AUTOSAR XML (schema 00047)
package /AppMode/ApplicationSwComponentTypes
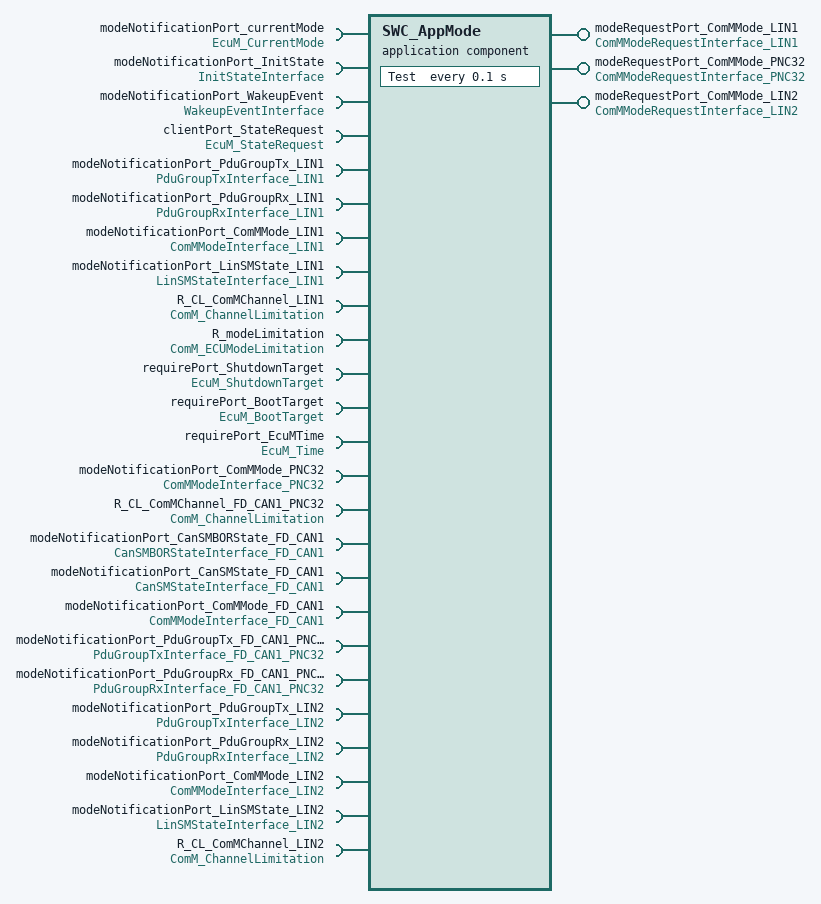
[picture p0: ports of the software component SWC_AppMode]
  application sw component type SWC_AppMode
    4 x require port:
      modeNotificationPort_currentMode: mode-switch-receiver-com-spec{enhanced-mode-api=true, mode-group=currentMode, supports-asynchronous-mode-switch=true}, required-interface=EcuM_CurrentMode
      modeNotificationPort_InitState: mode-switch-receiver-com-spec{enhanced-mode-api=true, mode-group=InitState, supports-asynchronous-mode-switch=true}, required-interface=InitStateInterface
      modeNotificationPort_WakeupEvent: mode-switch-receiver-com-spec{enhanced-mode-api=true, mode-group=WakeupEvent, supports-asynchronous-mode-switch=true}, required-interface=WakeupEventInterface
      clientPort_StateRequest: required-com-specs=[ReleaseRUN, RequestRUN, RequestSleep, RequestReset, RequestOff, ReleasePOST_RUN, RequestPOST_RUN], required-interface=EcuM_StateRequest
    provide port modeRequestPort_ComMMode_LIN1: nonqueued-sender-com-spec=data-element=ComMMode_LIN1, provided-interface=ComMModeRequestInterface_LIN1
    10 x require port:
      modeNotificationPort_PduGroupTx_LIN1: mode-switch-receiver-com-spec{enhanced-mode-api=true, mode-group=PduGroupTx_LIN1, supports-asynchronous-mode-switch=true}, required-interface=PduGroupTxInterface_LIN1
      modeNotificationPort_PduGroupRx_LIN1: mode-switch-receiver-com-spec{enhanced-mode-api=true, mode-group=PduGroupRx_LIN1, supports-asynchronous-mode-switch=true}, required-interface=PduGroupRxInterface_LIN1
      modeNotificationPort_ComMMode_LIN1: mode-switch-receiver-com-spec{enhanced-mode-api=true, mode-group=ComMMode_LIN1, supports-asynchronous-mode-switch=true}, required-interface=ComMModeInterface_LIN1
      modeNotificationPort_LinSMState_LIN1: mode-switch-receiver-com-spec{enhanced-mode-api=true, mode-group=LinSMState_LIN1, supports-asynchronous-mode-switch=true}, required-interface=LinSMStateInterface_LIN1
      R_CL_ComMChannel_LIN1: required-com-specs=[LimitChannelToNoComMode, GetInhibitionStatus], required-interface=ComM_ChannelLimitation
      R_modeLimitation: required-com-specs=[SetECUGroupClassification, LimitECUToNoComMode], required-interface=ComM_ECUModeLimitation
      requirePort_ShutdownTarget: required-com-specs=[GetLastShutdownTarget, GetShutdownTarget, SelectShutdownTarget], required-interface=EcuM_ShutdownTarget
      requirePort_BootTarget: required-com-specs=[GetBootTarget, SelectBootTarget], required-interface=EcuM_BootTarget
      requirePort_EcuMTime: required-com-specs=[GetWakeupTime, GetCurrentTime], required-interface=EcuM_Time
      modeNotificationPort_ComMMode_PNC32: mode-switch-receiver-com-spec{enhanced-mode-api=true, mode-group=ComMMode_PNC32, supports-asynchronous-mode-switch=true}, required-interface=ComMModeInterface_PNC32
    provide port modeRequestPort_ComMMode_PNC32: nonqueued-sender-com-spec=ComMMode_PNC32, provided-interface=ComMModeRequestInterface_PNC32
    6 x require port:
      R_CL_ComMChannel_FD_CAN1_PNC32: required-com-specs=[LimitChannelToNoComMode, GetInhibitionStatus], required-interface=ComM_ChannelLimitation
      modeNotificationPort_CanSMBORState_FD_CAN1: mode-switch-receiver-com-spec{enhanced-mode-api=true, mode-group=CanSMBORState_FD_CAN1, supports-asynchronous-mode-switch=true}, required-interface=CanSMBORStateInterface_FD_CAN1
      modeNotificationPort_CanSMState_FD_CAN1: mode-switch-receiver-com-spec{enhanced-mode-api=true, mode-group=CanSMState_FD_CAN1, supports-asynchronous-mode-switch=true}, required-interface=CanSMStateInterface_FD_CAN1
      modeNotificationPort_ComMMode_FD_CAN1: mode-switch-receiver-com-spec{enhanced-mode-api=true, mode-group=ComMMode_FD_CAN1, supports-asynchronous-mode-switch=true}, required-interface=ComMModeInterface_FD_CAN1
      modeNotificationPort_PduGroupTx_FD_CAN1_PNC32: mode-switch-receiver-com-spec{enhanced-mode-api=true, mode-group=PduGroupTx_FD_CAN1_PNC32, supports-asynchronous-mode-switch=true}, required-interface=PduGroupTxInterface_FD_CAN1_PNC32
      modeNotificationPort_PduGroupRx_FD_CAN1_PNC32: mode-switch-receiver-com-spec{enhanced-mode-api=true, mode-group=PduGroupRx_FD_CAN1_PNC32, supports-asynchronous-mode-switch=true}, required-interface=PduGroupRxInterface_FD_CAN1_PNC32
    provide port modeRequestPort_ComMMode_LIN2: nonqueued-sender-com-spec=ComMMode_LIN2, provided-interface=ComMModeRequestInterface_LIN2
    5 x require port:
      modeNotificationPort_PduGroupTx_LIN2: mode-switch-receiver-com-spec{enhanced-mode-api=true, mode-group=PduGroupTx_LIN2, supports-asynchronous-mode-switch=true}, required-interface=PduGroupTxInterface_LIN2
      modeNotificationPort_PduGroupRx_LIN2: mode-switch-receiver-com-spec{enhanced-mode-api=true, mode-group=PduGroupRx_LIN2, supports-asynchronous-mode-switch=true}, required-interface=PduGroupRxInterface_LIN2
      modeNotificationPort_ComMMode_LIN2: mode-switch-receiver-com-spec{enhanced-mode-api=true, mode-group=ComMMode_LIN2, supports-asynchronous-mode-switch=true}, required-interface=ComMModeInterface_LIN2
      modeNotificationPort_LinSMState_LIN2: mode-switch-receiver-com-spec{enhanced-mode-api=true, mode-group=LinSMState_LIN2, supports-asynchronous-mode-switch=true}, required-interface=LinSMStateInterface_LIN2
      R_CL_ComMChannel_LIN2: required-com-specs=[LimitChannelToNoComMode, GetInhibitionStatus], required-interface=ComM_ChannelLimitation
    behavior SwcIB_AppMode: data-type-mapping=[MAP_AppMode, MAP_ComMMode, MAP_PduRouter, EcuModeMap, MAP_CanSMBORState, MAP_InitState, MAP_PduGroup, MAP_WakeupEvent, MAP_LinSMState, MAP_ComMMode_PNC], handle-termination-and-restart=NO-SUPPORT
      timing event TE_AppMode_Test: start-on-event=Test, period=0.1
        disabled-mode:
          modeNotificationPort_currentMode.currentMode.ECUM_STATE_STARTUP_ONE
          modeNotificationPort_currentMode.currentMode.ECUM_STATE_STARTUP_TWO
          modeNotificationPort_currentMode.currentMode.ECUM_STATE_STARTUP_THREE
      31 x swc mode switch event, all with activation=ON-ENTRY:
        SMSE_Entry_EcuModeSwitched_modeNotificationPort_CurrentMode_CurrentMode_ECUM_STATE_APP_POST_RUN: start-on-event=EcuModeSwitched, mode=modeNotificationPort_currentMode.currentMode.ECUM_STATE_APP_POST_RUN
        SMSE_Entry_EcuModeSwitched_modeNotificationPort_CurrentMode_CurrentMode_ECUM_STATE_APP_RUN: start-on-event=EcuModeSwitched, mode=modeNotificationPort_currentMode.currentMode.ECUM_STATE_APP_RUN
        SMSE_Entry_EcuModeSwitched_modeNotificationPort_CurrentMode_CurrentMode_ECUM_STATE_OFF: start-on-event=EcuModeSwitched, mode=modeNotificationPort_currentMode.currentMode.ECUM_STATE_OFF
        SMSE_Entry_EcuModeSwitched_modeNotificationPort_CurrentMode_CurrentMode_ECUM_STATE_PREP_SHUTDOWN: start-on-event=EcuModeSwitched, mode=modeNotificationPort_currentMode.currentMode.ECUM_STATE_PREP_SHUTDOWN
        SMSE_Entry_EcuModeSwitched_modeNotificationPort_CurrentMode_CurrentMode_ECUM_STATE_RESET: start-on-event=EcuModeSwitched, mode=modeNotificationPort_currentMode.currentMode.ECUM_STATE_RESET
        SMSE_Entry_EcuModeSwitched_modeNotificationPort_CurrentMode_CurrentMode_ECUM_STATE_RUN: start-on-event=EcuModeSwitched, mode=modeNotificationPort_currentMode.currentMode.ECUM_STATE_RUN
        SMSE_Entry_EcuModeSwitched_modeNotificationPort_CurrentMode_CurrentMode_ECUM_STATE_SHUTDOWN: start-on-event=EcuModeSwitched, mode=modeNotificationPort_currentMode.currentMode.ECUM_STATE_SHUTDOWN
        SMSE_Entry_EcuModeSwitched_modeNotificationPort_CurrentMode_CurrentMode_ECUM_STATE_SLEEP: start-on-event=EcuModeSwitched, mode=modeNotificationPort_currentMode.currentMode.ECUM_STATE_SLEEP
        SMSE_Entry_InitCompleted_modeNotificationPort_InitState_InitState_COMPLETE: start-on-event=InitCompleted, mode=modeNotificationPort_InitState.InitState.COMPLETE
        SMSE_Entry_ComMModeSwitched_LIN1_modeNotificationPort_ComMMode_LIN1_ComMMode_LIN1_FULL_COM: start-on-event=ComMModeSwitched_LIN1, mode=modeNotificationPort_ComMMode_LIN1.ComMMode_LIN1.FULL_COM
        SMSE_Entry_ComMModeSwitched_LIN1_modeNotificationPort_ComMMode_LIN1_ComMMode_LIN1_NO_COM: start-on-event=ComMModeSwitched_LIN1, mode=modeNotificationPort_ComMMode_LIN1.ComMMode_LIN1.NO_COM
        SMSE_Entry_ComMModeSwitched_LIN1_modeNotificationPort_ComMMode_LIN1_ComMMode_LIN1_SILENT_COM: start-on-event=ComMModeSwitched_LIN1, mode=modeNotificationPort_ComMMode_LIN1.ComMMode_LIN1.SILENT_COM
        SMSE_Entry_PduGroupSwitched_FD_CAN1_PNC32_Tx_modeNotificationPort_PduGroupTx_FD_CAN1_PNC32_PduGroupTx_FD_CAN1_PNC32_START: start-on-event=PduGroupSwitched_FD_CAN1_PNC32_Tx, mode=modeNotificationPort_PduGroupTx_FD_CAN1_PNC32.PduGroupTx_FD_CAN1_PNC32.START
        SMSE_Entry_PduGroupSwitched_FD_CAN1_PNC32_Tx_modeNotificationPort_PduGroupTx_FD_CAN1_PNC32_PduGroupTx_FD_CAN1_PNC32_STOP: start-on-event=PduGroupSwitched_FD_CAN1_PNC32_Tx, mode=modeNotificationPort_PduGroupTx_FD_CAN1_PNC32.PduGroupTx_FD_CAN1_PNC32.STOP
        SMSE_Entry_CanSMBorStateSwitched_FD_CAN1_modeNotificationPort_CanSMBORState_FD_CAN1_CanSMBORState_FD_CAN1_COMPLETE: start-on-event=CanSMBorStateSwitched_FD_CAN1, mode=modeNotificationPort_CanSMBORState_FD_CAN1.CanSMBORState_FD_CAN1.COMPLETE
        SMSE_Entry_CanSMBorStateSwitched_FD_CAN1_modeNotificationPort_CanSMBORState_FD_CAN1_CanSMBORState_FD_CAN1_START: start-on-event=CanSMBorStateSwitched_FD_CAN1, mode=modeNotificationPort_CanSMBORState_FD_CAN1.CanSMBORState_FD_CAN1.START
        SMSE_Entry_ComMModeSwitched_FD_CAN1_PNC32_modeNotificationPort_ComMMode_PNC32_ComMMode_PNC32_PNC_FULL_COMMUNICATION: start-on-event=ComMModeSwitched_FD_CAN1_PNC32, mode=modeNotificationPort_ComMMode_PNC32.ComMMode_PNC32.PNC_FULL_COMMUNICATION
        SMSE_Entry_ComMModeSwitched_FD_CAN1_PNC32_modeNotificationPort_ComMMode_PNC32_ComMMode_PNC32_PNC_NO_COMMUNICATION: start-on-event=ComMModeSwitched_FD_CAN1_PNC32, mode=modeNotificationPort_ComMMode_PNC32.ComMMode_PNC32.PNC_NO_COMMUNICATION
        SMSE_Entry_ComMModeSwitched_FD_CAN1_PNC32_modeNotificationPort_ComMMode_PNC32_ComMMode_PNC32_PNC_PREPARE_SLEEP: start-on-event=ComMModeSwitched_FD_CAN1_PNC32, mode=modeNotificationPort_ComMMode_PNC32.ComMMode_PNC32.PNC_PREPARE_SLEEP
        SMSE_Entry_ComMModeSwitched_FD_CAN1_PNC32_modeNotificationPort_ComMMode_PNC32_ComMMode_PNC32_PNC_READY_SLEEP: start-on-event=ComMModeSwitched_FD_CAN1_PNC32, mode=modeNotificationPort_ComMMode_PNC32.ComMMode_PNC32.PNC_READY_SLEEP
        SMSE_Entry_ComMModeSwitched_FD_CAN1_PNC32_modeNotificationPort_ComMMode_PNC32_ComMMode_PNC32_PNC_REQUESTED: start-on-event=ComMModeSwitched_FD_CAN1_PNC32, mode=modeNotificationPort_ComMMode_PNC32.ComMMode_PNC32.PNC_REQUESTED
        SMSE_Entry_PduGroupSwitched_FD_CAN1_PNC32_Rx_modeNotificationPort_PduGroupRx_FD_CAN1_PNC32_PduGroupRx_FD_CAN1_PNC32_START: start-on-event=PduGroupSwitched_FD_CAN1_PNC32_Rx, mode=modeNotificationPort_PduGroupRx_FD_CAN1_PNC32.PduGroupRx_FD_CAN1_PNC32.START
        SMSE_Entry_PduGroupSwitched_FD_CAN1_PNC32_Rx_modeNotificationPort_PduGroupRx_FD_CAN1_PNC32_PduGroupRx_FD_CAN1_PNC32_STOP: start-on-event=PduGroupSwitched_FD_CAN1_PNC32_Rx, mode=modeNotificationPort_PduGroupRx_FD_CAN1_PNC32.PduGroupRx_FD_CAN1_PNC32.STOP
        SMSE_Entry_WakeupEventValidated_modeNotificationPort_WakeupEvent_WakeupEvent_FD_CAN1_RX: start-on-event=WakeupEventValidated, mode=modeNotificationPort_WakeupEvent.WakeupEvent.FD_CAN1_RX
        SMSE_Entry_WakeupEventValidated_modeNotificationPort_WakeupEvent_WakeupEvent_FD_CAN1_RX_POLL: start-on-event=WakeupEventValidated, mode=modeNotificationPort_WakeupEvent.WakeupEvent.FD_CAN1_RX_POLL
        SMSE_Entry_WakeupEventValidated_modeNotificationPort_WakeupEvent_WakeupEvent_HS_CAN1_RX: start-on-event=WakeupEventValidated, mode=modeNotificationPort_WakeupEvent.WakeupEvent.HS_CAN1_RX
        SMSE_Entry_WakeupEventValidated_modeNotificationPort_WakeupEvent_WakeupEvent_HS_CAN1_RX_POLL: start-on-event=WakeupEventValidated, mode=modeNotificationPort_WakeupEvent.WakeupEvent.HS_CAN1_RX_POLL
        SMSE_Entry_WakeupEventValidated_modeNotificationPort_WakeupEvent_WakeupEvent_LIN1_RX: start-on-event=WakeupEventValidated, mode=modeNotificationPort_WakeupEvent.WakeupEvent.LIN1_RX
        SMSE_Entry_ComMModeSwitched_LIN2_modeNotificationPort_ComMMode_LIN2_ComMMode_LIN2_FULL_COM: start-on-event=ComMModeSwitched_LIN2, mode=modeNotificationPort_ComMMode_LIN2.ComMMode_LIN2.FULL_COM
        SMSE_Entry_ComMModeSwitched_LIN2_modeNotificationPort_ComMMode_LIN2_ComMMode_LIN2_NO_COM: start-on-event=ComMModeSwitched_LIN2, mode=modeNotificationPort_ComMMode_LIN2.ComMMode_LIN2.NO_COM
        SMSE_Entry_ComMModeSwitched_LIN2_modeNotificationPort_ComMMode_LIN2_ComMMode_LIN2_SILENT_COM: start-on-event=ComMModeSwitched_LIN2, mode=modeNotificationPort_ComMMode_LIN2.ComMMode_LIN2.SILENT_COM
      10 x runnable:
        WakeupEventValidated: can-be-invoked-concurrently=true, symbol=AppMode_WakeupEventValidated
          data-send-points:
            access DSP_WakeupEventValidated_modeRequestPort_ComMMode_LIN1_ComMMode_LIN1: accessed-variable=modeRequestPort_ComMMode_LIN1.ComMMode_LIN1, scope=COMMUNICATION-INTER-ECU
            access DSP_WakeupEventValidated_modeRequestPort_ComMMode_PNC32_ComMMode_PNC32: accessed-variable=modeRequestPort_ComMMode_PNC32.ComMMode_PNC32, scope=COMMUNICATION-INTER-ECU
            access DSP_WakeupEventValidated_modeRequestPort_ComMMode_LIN2_ComMMode_LIN2: accessed-variable=modeRequestPort_ComMMode_LIN2.ComMMode_LIN2, scope=COMMUNICATION-INTER-ECU
          mode-access-point mode-group=modeNotificationPort_WakeupEvent.WakeupEvent:
            ident MRAP_WakeupEventValidated_modeNotificationPort_WakeupEvent_WakeupEvent
          sync call SSCP_WakeupEventValidated_clientPort_StateRequest_RequestRUN: operation=clientPort_StateRequest.RequestRUN, timeout=0.0
        Test: symbol=AppMode_Test
          data-send-points:
            access DSP_Test_modeRequestPort_ComMMode_LIN1_ComMMode_LIN1: accessed-variable=modeRequestPort_ComMMode_LIN1.ComMMode_LIN1, scope=COMMUNICATION-INTER-ECU
            access DSP_Test_modeRequestPort_ComMMode_PNC32_ComMMode_PNC32: accessed-variable=modeRequestPort_ComMMode_PNC32.ComMMode_PNC32, scope=COMMUNICATION-INTER-ECU
            access DSP_Test_modeRequestPort_ComMMode_LIN2_ComMMode_LIN2: accessed-variable=modeRequestPort_ComMMode_LIN2.ComMMode_LIN2, scope=COMMUNICATION-INTER-ECU
          20 x sync call:
            SSCP_Test_clientPort_StateRequest_RequestOff: operation=clientPort_StateRequest.RequestOff
            SSCP_Test_clientPort_StateRequest_RequestRUN: operation=clientPort_StateRequest.RequestRUN, timeout=0.0
            SSCP_Test_clientPort_StateRequest_RequestReset: operation=clientPort_StateRequest.RequestReset
            SSCP_Test_clientPort_StateRequest_RequestSleep: operation=clientPort_StateRequest.RequestSleep
            SSCP_Test_clientPort_StateRequest_ReleasePOST_RUN: operation=clientPort_StateRequest.ReleasePOST_RUN
            SSCP_Test_clientPort_StateRequest_RequestPOST_RUN: operation=clientPort_StateRequest.RequestPOST_RUN
            SSCP_Test_requirePort_ShutdownTarget_GetLastShutdownTarget: operation=requirePort_ShutdownTarget.GetLastShutdownTarget
            SSCP_Test_requirePort_ShutdownTarget_GetShutdownTarget: operation=requirePort_ShutdownTarget.GetShutdownTarget
            SSCP_Test_requirePort_ShutdownTarget_SelectShutdownTarget: operation=requirePort_ShutdownTarget.SelectShutdownTarget
            SSCP_Test_EcuM_Time_GetCurrentTime: operation=requirePort_EcuMTime.GetCurrentTime
            SSCP_Test_EcuM_Time_GetWakeupTime: operation=requirePort_EcuMTime.GetWakeupTime
            SSCP_Test_requirePort_BootTarget_GetBootTarget: operation=requirePort_BootTarget.GetBootTarget
            SSCP_Test_requirePort_BootTarget_SelectBootTarget: operation=requirePort_BootTarget.SelectBootTarget
            SSCP_Test_clientPort_StateRequest_ReleaseRUN: operation=clientPort_StateRequest.ReleaseRUN
            SSCP_Test_R_CL_ComMChannel_FD_CAN1_GetInhibitionStatus: operation=R_CL_ComMChannel_FD_CAN1_PNC32.GetInhibitionStatus, timeout=0.0
            SSCP_Test_R_CL_ComMChannel_FD_CAN1_LimitChannelToNoComMode: operation=R_CL_ComMChannel_FD_CAN1_PNC32.LimitChannelToNoComMode, timeout=0.0
            SSCP_Test_R_CL_ComMChannel_LIN1_GetInhibitionStatus: operation=R_CL_ComMChannel_LIN1.GetInhibitionStatus, timeout=0.0
            SSCP_Test_R_CL_ComMChannel_LIN1_LimitChannelToNoComMode: operation=R_CL_ComMChannel_LIN1.LimitChannelToNoComMode, timeout=0.0
            SSCP_Test_R_CL_ComMChannel_LIN2_GetInhibitionStatus: operation=R_CL_ComMChannel_LIN2.GetInhibitionStatus
            SSCP_Test_R_CL_ComMChannel_LIN2_LimitChannelToNoComMode: operation=R_CL_ComMChannel_LIN2.LimitChannelToNoComMode
        EcuModeSwitched: can-be-invoked-concurrently=true, symbol=AppMode_EcuModeSwitched
          data-send-points:
            access DSP_EcuModeSwitched_modeRequestPort_ComMMode_LIN1_ComMMode_LIN1: accessed-variable=modeRequestPort_ComMMode_LIN1.ComMMode_LIN1, scope=COMMUNICATION-INTER-ECU
            access DSP_EcuModeSwitched_modeRequestPort_ComMMode_PNC32_ComMMode_PNC32: accessed-variable=modeRequestPort_ComMMode_PNC32.ComMMode_PNC32, scope=COMMUNICATION-INTER-ECU
            access DSP_EcuModeSwitched_modeRequestPort_ComMMode_LIN2_ComMMode_LIN2: accessed-variable=modeRequestPort_ComMMode_LIN2.ComMMode_LIN2, scope=COMMUNICATION-INTER-ECU
          mode-access-point mode-group=modeNotificationPort_currentMode.currentMode:
            ident MRAP_EcuModeSwitched_modeNotificationPort_CurrentMode_CurrentMode
          9 x sync call:
            SSCP_EcuModeSwitched_clientPort_StateRequest_RequestRUN: operation=clientPort_StateRequest.RequestRUN
            SSCP_EcuModeSwitched_R_modeLimitation_LimitECUToNoComMode: operation=R_modeLimitation.LimitECUToNoComMode
            SSCP_EcuModeSwitched_R_CL_ComMChannel_LIN1_LimitChannelToNoComMode: operation=R_CL_ComMChannel_LIN1.LimitChannelToNoComMode
            SSCP_EcuModeSwitched_R_CL_ComMChannel_LIN1_GetInhibitionStatus: operation=R_CL_ComMChannel_LIN1.GetInhibitionStatus
            SSCP_EcuModeSwitched_R_modeLimitation_SetECUGroupClassification: operation=R_modeLimitation.SetECUGroupClassification
            SSCP_EcuModeSwitched_R_CL_ComMChannel_FD_CAN1_GetInhibitionStatus: operation=R_CL_ComMChannel_FD_CAN1_PNC32.GetInhibitionStatus
            SSCP_EcuModeSwitched_R_CL_ComMChannel_FD_CAN1_LimitChannelToNoComMode: operation=R_CL_ComMChannel_FD_CAN1_PNC32.LimitChannelToNoComMode
            SSCP_EcuModeSwitched_R_CL_ComMChannel_LIN2_GetInhibitionStatus: operation=R_CL_ComMChannel_LIN2.GetInhibitionStatus, timeout=0.0
            SSCP_EcuModeSwitched_R_CL_ComMChannel_LIN2_LimitChannelToNoComMode: operation=R_CL_ComMChannel_LIN2.LimitChannelToNoComMode, timeout=0.0
        InitCompleted: can-be-invoked-concurrently=true, symbol=AppMode_InitCompleted
          mode-access-point mode-group=modeNotificationPort_InitState.InitState:
            ident MRAP_InitCompleted_modeNotificationPort_InitState_InitState
        ComMModeSwitched_LIN1: can-be-invoked-concurrently=true, symbol=AppMode_ComMModeSwitched_LIN1
          mode-access-point mode-group=modeNotificationPort_ComMMode_LIN1.ComMMode_LIN1:
            ident MRAP_ComMModeSwitched_LIN1_modeNotificationPort_ComMMode_LIN1_ComMMode_LIN1
        CanSMBorStateSwitched_FD_CAN1: can-be-invoked-concurrently=true, symbol=AppMode_CanSMBorStateSwitched_FD_CAN1
          mode-access-point mode-group=modeNotificationPort_CanSMBORState_FD_CAN1.CanSMBORState_FD_CAN1:
            ident MRAP_CanSMBorStateSwitched_FD_CAN1_modeNotificationPort_CanSMBORState_FD_CAN1_CanSMBORState_FD_CAN1
        ComMModeSwitched_FD_CAN1_PNC32: can-be-invoked-concurrently=true, symbol=AppMode_ComMModeSwitched_FD_CAN1_PNC32
          mode-access-point mode-group=modeNotificationPort_ComMMode_PNC32.ComMMode_PNC32:
            ident MRAP_ComMModeSwitched_FD_CAN1_PNC32_modeNotificationPort_ComMMode_PNC32_ComMMode_PNC32
        PduGroupSwitched_FD_CAN1_PNC32_Tx: can-be-invoked-concurrently=true, symbol=AppMode_PduGroupSwitched_FD_CAN1_PNC32_Tx
          mode-access-point mode-group=modeNotificationPort_PduGroupTx_FD_CAN1_PNC32.PduGroupTx_FD_CAN1_PNC32:
            ident MRAP_PduGroupSwitched_FD_CAN1_PNC32_Tx_modeNotificationPort_PduGroupTx_FD_CAN1_PNC32_PduGroupTx_FD_CAN1_PNC32
        PduGroupSwitched_FD_CAN1_PNC32_Rx: can-be-invoked-concurrently=true, symbol=AppMode_PduGroupSwitched_FD_CAN1_PNC32_Rx
          mode-access-point mode-group=modeNotificationPort_PduGroupRx_FD_CAN1_PNC32.PduGroupRx_FD_CAN1_PNC32:
            ident MRAP_PduGroupSwitched_FD_CAN1_PNC32_Rx_modeNotificationPort_PduGroupRx_FD_CAN1_PNC32_PduGroupRx_FD_CAN1_PNC32
        ComMModeSwitched_LIN2: can-be-invoked-concurrently=true, symbol=AppMode_ComMModeSwitched_LIN2
          mode-access-point mode-group=modeNotificationPort_ComMMode_LIN2.ComMMode_LIN2:
            ident MRAP_ComMModeSwitched_LIN2_modeNotificationPort_ComMMode_LIN2_ComMMode_LIN2
      swc service dependency SwcServiceDependency_BswM
        assigned-ports:
          port-prototype=modeNotificationPort_InitState, role=Custom
          port-prototype=modeNotificationPort_WakeupEvent, role=Custom
          port-prototype=modeNotificationPort_ComMMode_LIN1, role=Custom
          port-prototype=modeNotificationPort_LinSMState_LIN1, role=Custom
          port-prototype=modeNotificationPort_PduGroupRx_LIN1, role=Custom
          port-prototype=modeNotificationPort_PduGroupTx_LIN1, role=Custom
          port-prototype=modeRequestPort_ComMMode_LIN1, role=Custom
          port-prototype=modeNotificationPort_ComMMode_PNC32, role=Custom
          port-prototype=modeRequestPort_ComMMode_PNC32, role=Custom
          port-prototype=modeNotificationPort_ComMMode_PNC32, role=Custom
          port-prototype=modeRequestPort_ComMMode_PNC32, role=Custom
          port-prototype=modeNotificationPort_CanSMBORState_FD_CAN1, role=Custom
          port-prototype=modeNotificationPort_CanSMState_FD_CAN1, role=Custom
          port-prototype=modeNotificationPort_ComMMode_FD_CAN1, role=Custom
          port-prototype=modeNotificationPort_PduGroupTx_FD_CAN1_PNC32, role=Custom
          port-prototype=modeNotificationPort_PduGroupRx_FD_CAN1_PNC32, role=Custom
          port-prototype=modeNotificationPort_ComMMode_LIN2, role=Custom
          port-prototype=modeNotificationPort_PduGroupRx_LIN2, role=Custom
          port-prototype=modeNotificationPort_PduGroupTx_LIN2, role=Custom
          port-prototype=modeRequestPort_ComMMode_LIN2, role=Custom
          port-prototype=modeNotificationPort_LinSMState_LIN2, role=Custom
        service-needs:
          bsw mgr needs BswMgrNeeds
